VERSION ""

NS_ :

BS_:

BU_: MASTER SENSOR GEO ANDROID MOTOR

BO_ 120 HEARTBEAT: 1 MASTER
 SG_ HEARTBEAT_cmd : 0|8@1+ (1,0) [0|0] "" SENSOR,MOTOR,ANDROID,GEO

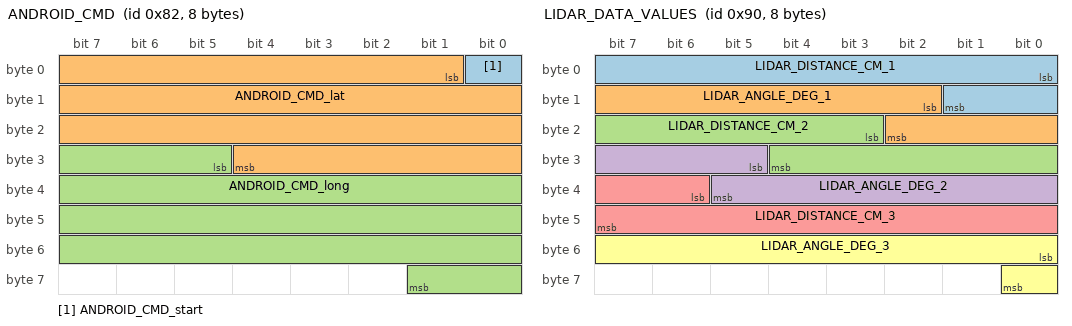
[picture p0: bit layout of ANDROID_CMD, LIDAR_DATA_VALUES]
BO_ 130 ANDROID_CMD: 8 ANDROID
 SG_ ANDROID_CMD_start : 0|1@1+ (1,0) [0|0] "" MASTER
 SG_ ANDROID_CMD_lat : 1|28@1+ (0.000001,-90.000000) [-90|90] "Degrees" MASTER
 SG_ ANDROID_CMD_long : 29|29@1+ (0.000001,-180.000000) [-180|180] "Degrees" MASTER

BO_ 140 CAR_CONTROL: 2 MASTER
 SG_ CAR_CONTROL_speed : 0|8@1+ (1,0) [0|0] "mph" MOTOR
 SG_ CAR_CONTROL_steer : 8|8@1+ (1,0) [0|0] "" MOTOR

BO_ 144 LIDAR_DATA_VALUES: 8 SENSOR
 SG_ LIDAR_DISTANCE_CM_1 : 0|10@1+ (1,0) [0|600] "" MASTER,MOTOR,ANDROID
 SG_ LIDAR_ANGLE_DEG_1 : 10|9@1+ (1,0) [0|360] "" MASTER,MOTOR,ANDROID
 SG_ LIDAR_DISTANCE_CM_2 : 19|10@1+ (1,0) [0|600] "" MASTER,MOTOR,ANDROID
 SG_ LIDAR_ANGLE_DEG_2 : 29|9@1+ (1,0) [0|360] "" MASTER,MOTOR,ANDROID
 SG_ LIDAR_DISTANCE_CM_3 : 38|10@1+ (1,0) [0|600] "" MASTER,MOTOR,ANDROID
 SG_ LIDAR_ANGLE_DEG_3 : 48|9@1+ (1,0) [0|360] "" MASTER,MOTOR,ANDROID

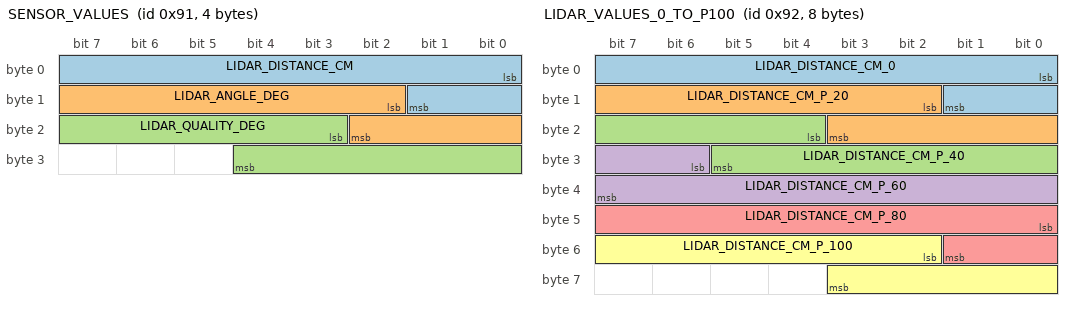
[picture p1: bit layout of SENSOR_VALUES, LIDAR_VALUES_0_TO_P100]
BO_ 145 SENSOR_VALUES: 4 SENSOR
 SG_ LIDAR_DISTANCE_CM : 0|10@1+ (1,0) [0|600] "" MASTER,MOTOR,ANDROID
 SG_ LIDAR_ANGLE_DEG : 10|9@1+ (1,0) [0|360] "" MASTER,MOTOR,ANDROID
 SG_ LIDAR_QUALITY_DEG : 19|10@1+ (1,0) [0|128] "" MASTER,MOTOR,ANDROID

BO_ 146 LIDAR_VALUES_0_TO_P100: 8 SENSOR
 SG_ LIDAR_DISTANCE_CM_0 : 0|10@1+ (1,0) [0|600] "" MASTER,MOTOR,ANDROID
 SG_ LIDAR_DISTANCE_CM_P_20 : 10|10@1+ (1,0) [0|600] "" MASTER,MOTOR,ANDROID
 SG_ LIDAR_DISTANCE_CM_P_40 : 20|10@1+ (1,0) [0|600] "" MASTER,MOTOR,ANDROID
 SG_ LIDAR_DISTANCE_CM_P_60 : 30|10@1+ (1,0) [0|600] "" MASTER,MOTOR,ANDROID
 SG_ LIDAR_DISTANCE_CM_P_80 : 40|10@1+ (1,0) [0|600] "" MASTER,MOTOR,ANDROID
 SG_ LIDAR_DISTANCE_CM_P_100 : 50|10@1+ (1,0) [0|600] "" MASTER,MOTOR,ANDROID

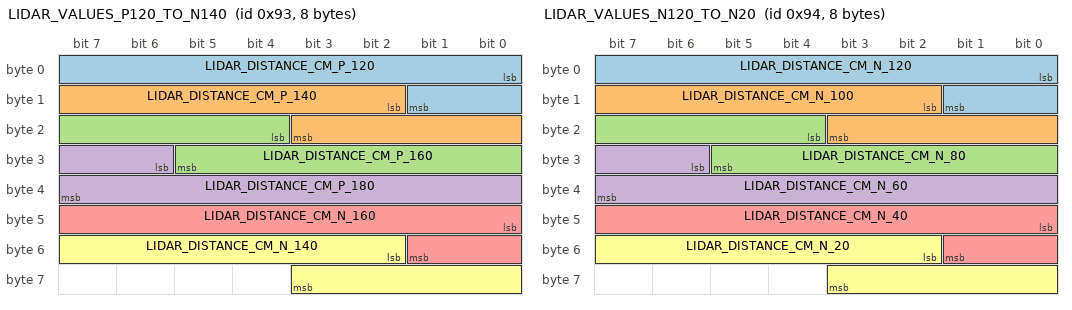
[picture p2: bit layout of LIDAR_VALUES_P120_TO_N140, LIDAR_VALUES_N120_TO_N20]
BO_ 147 LIDAR_VALUES_P120_TO_N140: 8 SENSOR
 SG_ LIDAR_DISTANCE_CM_P_120 : 0|10@1+ (1,0) [0|600] "" MASTER,MOTOR,ANDROID
 SG_ LIDAR_DISTANCE_CM_P_140 : 10|10@1+ (1,0) [0|600] "" MASTER,MOTOR,ANDROID
 SG_ LIDAR_DISTANCE_CM_P_160 : 20|10@1+ (1,0) [0|600] "" MASTER,MOTOR,ANDROID
 SG_ LIDAR_DISTANCE_CM_P_180 : 30|10@1+ (1,0) [0|600] "" MASTER,MOTOR,ANDROID
 SG_ LIDAR_DISTANCE_CM_N_160 : 40|10@1+ (1,0) [0|600] "" MASTER,MOTOR,ANDROID
 SG_ LIDAR_DISTANCE_CM_N_140 : 50|10@1+ (1,0) [0|600] "" MASTER,MOTOR,ANDROID

BO_ 148 LIDAR_VALUES_N120_TO_N20: 8 SENSOR
 SG_ LIDAR_DISTANCE_CM_N_120 : 0|10@1+ (1,0) [0|600] "" MASTER,MOTOR,ANDROID
 SG_ LIDAR_DISTANCE_CM_N_100 : 10|10@1+ (1,0) [0|600] "" MASTER,MOTOR,ANDROID
 SG_ LIDAR_DISTANCE_CM_N_80 : 20|10@1+ (1,0) [0|600] "" MASTER,MOTOR,ANDROID
 SG_ LIDAR_DISTANCE_CM_N_60 : 30|10@1+ (1,0) [0|600] "" MASTER,MOTOR,ANDROID
 SG_ LIDAR_DISTANCE_CM_N_40 : 40|10@1+ (1,0) [0|600] "" MASTER,MOTOR,ANDROID
 SG_ LIDAR_DISTANCE_CM_N_20 : 50|10@1+ (1,0) [0|600] "" MASTER,MOTOR,ANDROID

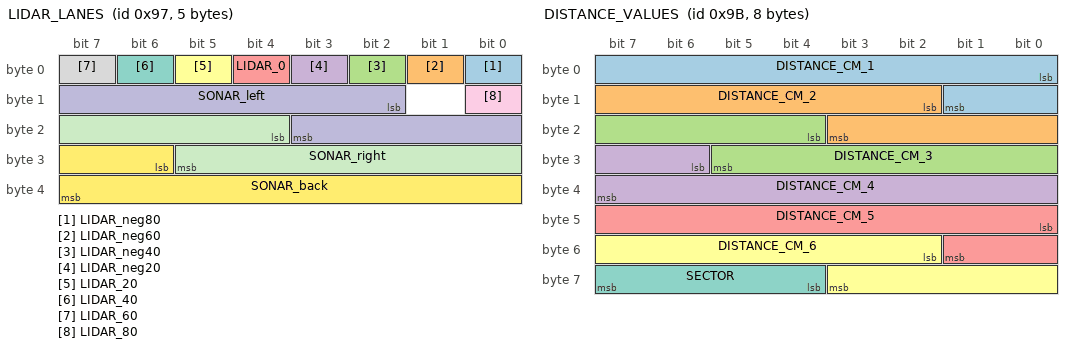
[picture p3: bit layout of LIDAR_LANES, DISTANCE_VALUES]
BO_ 151 LIDAR_LANES: 5 SENSOR
 SG_ LIDAR_neg80 : 0|1@1+ (1,0) [0|1] "" MASTER,MOTOR,ANDROID
 SG_ LIDAR_neg60 : 1|1@1+ (1,0) [0|1] "" MASTER,MOTOR,ANDROID
 SG_ LIDAR_neg40 : 2|1@1+ (1,0) [0|1] "" MASTER,MOTOR,ANDROID
 SG_ LIDAR_neg20 : 3|1@1+ (1,0) [0|1] "" MASTER,MOTOR,ANDROID
 SG_ LIDAR_0 : 4|1@1+ (1,0) [0|1] "" MASTER,MOTOR,ANDROID
 SG_ LIDAR_20 : 5|1@1+ (1,0) [0|1] "" MASTER,MOTOR,ANDROID
 SG_ LIDAR_40 : 6|1@1+ (1,0) [0|1] "" MASTER,MOTOR,ANDROID
 SG_ LIDAR_60 : 7|1@1+ (1,0) [0|1] "" MASTER,MOTOR,ANDROID
 SG_ LIDAR_80 : 8|1@1+ (1,0) [0|1] "" MASTER,MOTOR,ANDROID
 SG_ SONAR_left : 10|10@1+ (1,0) [0|645] "" MASTER,MOTOR,ANDROID
 SG_ SONAR_right : 20|10@1+ (1,0) [0|645] "" MASTER,MOTOR,ANDROID
 SG_ SONAR_back : 30|10@1+ (1,0) [0|645] "" MASTER,MOTOR,ANDROID

BO_ 150 SENSOR_DATA: 4 SENSOR
 SG_ LIDAR_neg160 : 0|1@1+ (1,0) [0|1] "" MASTER,MOTOR,ANDROID
 SG_ LIDAR_neg140 : 1|1@1+ (1,0) [0|1] "" MASTER,MOTOR,ANDROID
 SG_ LIDAR_neg120 : 2|1@1+ (1,0) [0|1] "" MASTER,MOTOR,ANDROID
 SG_ LIDAR_neg100 : 3|1@1+ (1,0) [0|1] "" MASTER,MOTOR,ANDROID
 SG_ LIDAR_neg80 : 4|1@1+ (1,0) [0|1] "" MASTER,MOTOR,ANDROID
 SG_ LIDAR_neg60 : 5|1@1+ (1,0) [0|1] "" MASTER,MOTOR,ANDROID
 SG_ LIDAR_neg40 : 6|1@1+ (1,0) [0|1] "" MASTER,MOTOR,ANDROID
 SG_ LIDAR_neg20 : 7|1@1+ (1,0) [0|1] "" MASTER,MOTOR,ANDROID
 SG_ LIDAR_0 : 8|1@1+ (1,0) [0|1] "" MASTER,MOTOR,ANDROID
 SG_ LIDAR_20 : 9|1@1+ (1,0) [0|1] "" MASTER,MOTOR,ANDROID
 SG_ LIDAR_40 : 10|1@1+ (1,0) [0|1] "" MASTER,MOTOR,ANDROID
 SG_ LIDAR_60 : 11|1@1+ (1,0) [0|1] "" MASTER,MOTOR,ANDROID
 SG_ LIDAR_80 : 12|1@1+ (1,0) [0|1] "" MASTER,MOTOR,ANDROID
 SG_ LIDAR_100 : 13|1@1+ (1,0) [0|1] "" MASTER,MOTOR,ANDROID
 SG_ LIDAR_120 : 14|1@1+ (1,0) [0|1] "" MASTER,MOTOR,ANDROID
 SG_ LIDAR_140 : 15|1@1+ (1,0) [0|1] "" MASTER,MOTOR,ANDROID
 SG_ LIDAR_160 : 16|1@1+ (1,0) [0|1] "" MASTER,MOTOR,ANDROID
 SG_ LIDAR_180 : 17|1@1+ (1,0) [0|1] "" MASTER,MOTOR,ANDROID
 SG_ SONAR_front : 18|10@1+ (1,0) [0|645] "" MASTER,MOTOR,ANDROID

BO_ 155 DISTANCE_VALUES: 8 SENSOR
 SG_ DISTANCE_CM_1 : 0|10@1+ (1,0) [0|600] "" MASTER,MOTOR,ANDROID
 SG_ DISTANCE_CM_2 : 10|10@1+ (1,0) [0|600] "" MASTER,MOTOR,ANDROID
 SG_ DISTANCE_CM_3 : 20|10@1+ (1,0) [0|600] "" MASTER,MOTOR,ANDROID
 SG_ DISTANCE_CM_4 : 30|10@1+ (1,0) [0|600] "" MASTER,MOTOR,ANDROID
 SG_ DISTANCE_CM_5 : 40|10@1+ (1,0) [0|600] "" MASTER,MOTOR,ANDROID
 SG_ DISTANCE_CM_6 : 50|10@1+ (1,0) [0|600] "" MASTER,MOTOR,ANDROID
 SG_ SECTOR : 60|4@1+ (1,0) [0|6] "" MASTER,MOTOR,ANDROID

BO_ 160 GPS_DATA: 8 GEO
 SG_ GPS_LATITUDE : 0|28@1+ (0.000001,-90.000000) [-90|90] "Degrees" MASTER,MOTOR,ANDROID
 SG_ GPS_LONGITUDE : 28|29@1+ (0.000001,-180.000000) [-180|180] "Degrees" MASTER,MOTOR,ANDROID

BO_ 170 COMPASS: 8 GEO
 SG_ CMP_HEADING : 0|32@1+ (1,0) [0|0] "Degrees" MASTER,MOTOR,ANDROID
 SG_ CMP_BEARING : 32|32@1+ (1,0) [0|0] "Degrees" MASTER,MOTOR,ANDROID

BO_ 180 MOTOR_DATA: 1 MOTOR
 SG_ CAR_SPEED : 0|5@1+ (1,0) [0|0] "mph" MASTER

BO_ 190 MOTOR_TELEMETRY: 8 MOTOR
 SG_ MOTOR_TELEMETRY_pwm : 0|16@1+ (0.1,0) [0|30] "PWM" MASTER,ANDROID
 SG_ MOTOR_TELEMETRY_kph : 16|16@1+ (0.1,0) [0|0] "kph" MASTER,ANDROID

CM_ BU_ MASTER "Master controller is heart of the system and will control other boards";
CM_ BU_ MOTOR "Motor will drive the wheels of car and display data on LCD";
CM_ BU_ SENSOR "Sensor will help in obstacle detection and avoidance";
CM_ BU_ GEO "Geo will help in navigation";
CM_ BU_ ANDROID "User sets destination and commands to start-stop the car";

BA_ "FieldType" SG_ 120 HEARTBEAT_cmd "HEARTBEAT_cmd";

VAL_ 120 HEARTBEAT_cmd 2 "HEARTBEAT_cmd_REBOOT" 1 "HEARTBEAT_cmd_SYNC" 0 "HEARTBEAT_cmd_NOOP" ;
